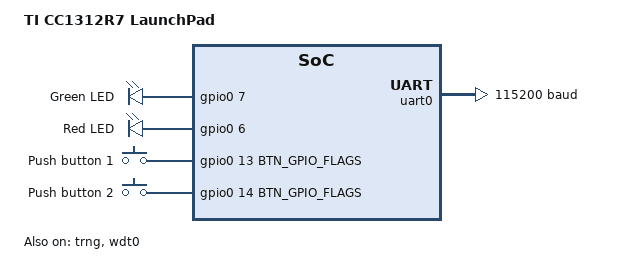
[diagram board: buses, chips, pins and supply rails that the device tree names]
/*
 * TI LP-CC1312R7 LaunchPad, out of tree for csim.
 * SPDX-License-Identifier: Apache-2.0
 *
 * Pins from TI's LP_CC1312R7.syscfg.json (SimpleLink F2 SDK lpf2-8.33.00.16):
 * XDS110 UART RXD/TXD on package pins 7/8 = DIO2/DIO3, red/green LED on
 * pins 11/12 = DIO6/DIO7, BTN-1/BTN-2 on pins 19/20 = DIO13/DIO14 (no
 * external pull).
 */

/dts-v1/;

#include <ti/cc1352r7.dtsi>
#include <zephyr/dt-bindings/pinctrl/cc13xx_cc26xx-pinctrl.h>
#include <zephyr/dt-bindings/input/input-event-codes.h>

#define BTN_GPIO_FLAGS (GPIO_ACTIVE_LOW | GPIO_PULL_UP)

/ {
	model = "TI CC1312R7 LaunchPad";
	compatible = "ti,lp-cc1312r7";

	aliases {
		led0 = &led0;
		led1 = &led1;
		sw0 = &btn0;
		sw1 = &btn1;
		watchdog0 = &wdt0;
	};

	chosen {
		zephyr,sram = &sram0;
		zephyr,flash = &flash0;
		zephyr,console = &uart0;
		zephyr,shell-uart = &uart0;
	};

	leds {
		compatible = "gpio-leds";

		led0: led_0 {
			gpios = <&gpio0 7 GPIO_ACTIVE_HIGH>;
			label = "Green LED";
		};

		led1: led_1 {
			gpios = <&gpio0 6 GPIO_ACTIVE_HIGH>;
			label = "Red LED";
		};
	};

	keys {
		compatible = "gpio-keys";

		btn0: btn_0 {
			gpios = <&gpio0 13 BTN_GPIO_FLAGS>;
			label = "Push button 1";
			zephyr,code = <INPUT_KEY_0>;
		};

		btn1: btn_1 {
			gpios = <&gpio0 14 BTN_GPIO_FLAGS>;
			label = "Push button 2";
			zephyr,code = <INPUT_KEY_1>;
		};
	};
};

&pinctrl {
	uart0_tx_default: uart0_tx_default {
		pinmux = <3 IOC_PORT_MCU_UART0_TX>;
		bias-disable;
	};

	uart0_rx_default: uart0_rx_default {
		pinmux = <2 IOC_PORT_MCU_UART0_RX>;
		bias-disable;
		input-enable;
	};
};

&cpu0 {
	clock-frequency = <48000000>;
};

&trng {
	status = "okay";
};

&gpio0 {
	status = "okay";
};

&uart0 {
	status = "okay";
	current-speed = <115200>;
	pinctrl-0 = <&uart0_rx_default &uart0_tx_default>;
	pinctrl-names = "default";
};

&wdt0 {
	status = "okay";
};
